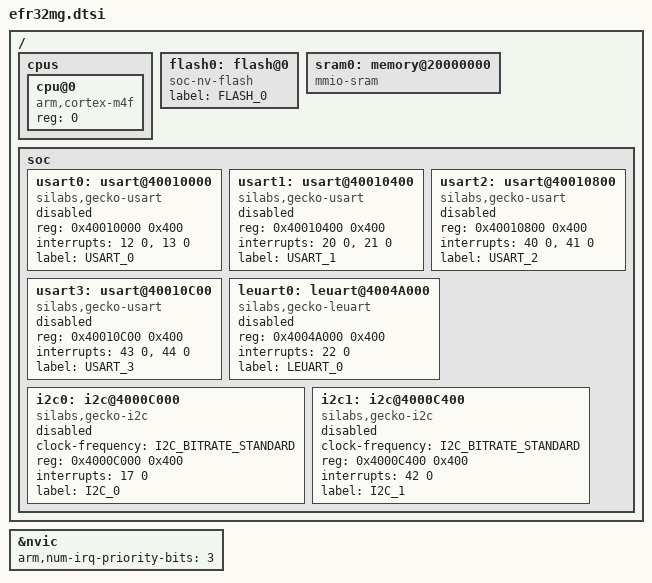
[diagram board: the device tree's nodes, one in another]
#include <arm/armv7-m.dtsi>
#include <dt-bindings/i2c/i2c.h>

/ {
	cpus {
		#address-cells = <1>;
		#size-cells = <0>;

		cpu@0 {
			compatible = "arm,cortex-m4f";
			reg = <0>;
		};
	};

	flash0: flash@0 {
		compatible = "soc-nv-flash";
		label = "FLASH_0";
	};

	sram0: memory@20000000 {
		device_type = "memory";
		compatible = "mmio-sram";
	};

	soc {
		usart0: usart@40010000 { /* USART0 */
			compatible = "silabs,gecko-usart";
			reg = <0x40010000 0x400>;
			interrupts = <12 0>, <13 0>;
			interrupt-names = "rx", "tx";
			status = "disabled";
			label = "USART_0";
		};

		usart1: usart@40010400 { /* USART1 */
			compatible = "silabs,gecko-usart";
			reg = <0x40010400 0x400>;
			interrupts = <20 0>, <21 0>;
			interrupt-names = "rx", "tx";
			status = "disabled";
			label = "USART_1";
		};

		usart2: usart@40010800 { /* USART2 */
			compatible = "silabs,gecko-usart";
			reg = <0x40010800 0x400>;
			interrupts = <40 0>, <41 0>;
			interrupt-names = "rx", "tx";
			status = "disabled";
			label = "USART_2";
		};

		usart3: usart@40010C00 { /* USART3 */
			compatible = "silabs,gecko-usart";
			reg = <0x40010C00 0x400>;
			interrupts = <43 0>, <44 0>;
			interrupt-names = "rx", "tx";
			status = "disabled";
			label = "USART_3";
		};

		leuart0: leuart@4004A000 { /* LEUART0 */
			compatible = "silabs,gecko-leuart";
			reg = <0x4004A000 0x400>;
			interrupts = <22 0>;
			status = "disabled";
			label = "LEUART_0";
		};

		i2c0: i2c@4000C000 {
			compatible = "silabs,gecko-i2c";
			clock-frequency = <I2C_BITRATE_STANDARD>;
			#address-cells = <1>;
			#size-cells = <0>;
			reg = <0x4000C000 0x400>;
			interrupts = <17 0>;
			label = "I2C_0";
			status = "disabled";
		};

		i2c1: i2c@4000C400 {
			compatible = "silabs,gecko-i2c";
			clock-frequency = <I2C_BITRATE_STANDARD>;
			#address-cells = <1>;
			#size-cells = <0>;
			reg = <0x4000C400 0x400>;
			interrupts = <42 0>;
			label = "I2C_1";
			status = "disabled";
		};
	};
};

&nvic {
	arm,num-irq-priority-bits = <3>;
};
